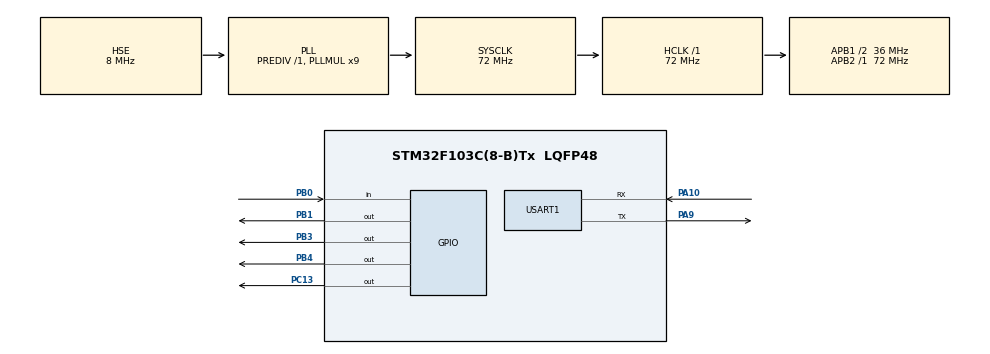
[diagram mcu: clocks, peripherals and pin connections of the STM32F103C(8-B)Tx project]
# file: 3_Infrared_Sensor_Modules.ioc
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Mcu.Family=STM32F1
RCC.PLLSourceVirtual=RCC_PLLSOURCE_HSE
PD1-OSC_OUT.Mode=HSE-External-Oscillator
PA10.Mode=Asynchronous
PC13-TAMPER-RTC.Signal=GPIO_Output
PD0-OSC_IN.Signal=RCC_OSC_IN
RCC.APB1CLKDivider=RCC_HCLK_DIV2
RCC.SYSCLKSource=RCC_SYSCLKSOURCE_PLLCLK
ProjectManager.StackSize=0x400
PD1-OSC_OUT.Signal=RCC_OSC_OUT
PA13.Signal=SYS_JTMS-SWDIO
PA9.Mode=Asynchronous
ProjectManager.TargetToolchain=STM32CubeIDE
RCC.HCLKFreq_Value=72000000
RCC.APB2TimFreq_Value=72000000
PA9.Signal=USART1_TX
RCC.USBFreq_Value=72000000
RCC.AHBFreq_Value=72000000
PD0-OSC_IN.Mode=HSE-External-Oscillator
board=custom
RCC.PLLMUL=RCC_PLL_MUL9
RCC.APB2Freq_Value=72000000
PA14.Mode=Serial_Wire
PA13.Mode=Serial_Wire
Mcu.Name=STM32F103C(8-B)Tx
VP_TIM1_VS_ClockSourceINT.Mode=Internal
PB3.Signal=GPIO_Output
RCC.SYSCLKFreq_VALUE=72000000
Mcu.Package=LQFP48
PB1.Signal=GPIO_Output
USART1.VirtualMode=VM_ASYNC
PA10.Signal=USART1_RX
PA14.Signal=SYS_JTCK-SWCLK
ProjectManager.HeapSize=0x200
NVIC.PriorityGroup=NVIC_PRIORITYGROUP_4
RCC.APB1TimFreq_Value=72000000
RCC.APB1Freq_Value=36000000
PB0.Signal=GPIO_Input
PB4.Signal=GPIO_Output

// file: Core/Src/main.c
/* USER CODE BEGIN Header */
/**
 ******************************************************************************
 * @file           : main.c
 * @brief          : Main program body
 ******************************************************************************
 * @attention
 *
 * <h2><center>&copy; Copyright (c) 2021 STMicroelectronics.
 * All rights reserved.</center></h2>
 *
 * This software component is licensed by ST under BSD 3-Clause license,
 * the "License"; You may not use this file except in compliance with the
 * License. You may obtain a copy of the License at:
 *                        opensource.org/licenses/BSD-3-Clause
 *
 ******************************************************************************
 */
/* infaredSensor.h
 * Released : 27/03/2021
 * Author   : danghoanelec@gmail.com
 * Short Descriptions:
  The library is using NEC Infrared Transmission Protocol to send/receive data
 * */

/* USER CODE END Header */
#include "main.h"

/* USER CODE BEGIN Includes */
//#include "stm32f1xx_hal_tim.h"
#include "infraredSensor.h"
/* USER CODE END Includes */

TIM_HandleTypeDef htim1;

UART_HandleTypeDef huart1;

void SystemClock_Config(void);
static void MX_GPIO_Init(void);
static void MX_TIM1_Init(void);
static void MX_USART1_UART_Init(void);

int main(void) {

	/* MCU Configuration--------------------------------------------------------*/

	/* Reset of all peripherals, Initializes the Flash interface and the Systick. */
	HAL_Init();

	/* Configure the system clock */
	SystemClock_Config();

	/* Initialize all configured peripherals */
	MX_GPIO_Init();
	MX_TIM1_Init();
	MX_USART1_UART_Init();
	/* USER CODE BEGIN 2 */
	Timer_1us_Init(72, htim1, TIM1);
	/* USER CODE END 2 */

	/* Infinite loop */
	/* USER CODE BEGIN WHILE */
	while (1) {
		uint32_t frm = NEC_Infrared_Read_specify(0x01);
		uint8_t data = NEC_Infrared_get_Data(frm);
		if(data != IR_RECEIVE_FAIL)
		{
			HAL_GPIO_TogglePin(GPIOC, GPIO_PIN_13);
		}
		//NEC_Infrared_Send_Data(0x01, 0x01);
	}
	/* USER CODE END 3 */
}

void SystemClock_Config(void) {
	RCC_OscInitTypeDef RCC_OscInitStruct = { 0 };
	RCC_ClkInitTypeDef RCC_ClkInitStruct = { 0 };

	/** Initializes the RCC Oscillators according to the specified parameters
	 * in the RCC_OscInitTypeDef structure.
	 */
	RCC_OscInitStruct.OscillatorType = RCC_OSCILLATORTYPE_HSE;
	RCC_OscInitStruct.HSEState = RCC_HSE_ON;
	RCC_OscInitStruct.HSEPredivValue = RCC_HSE_PREDIV_DIV1;
	RCC_OscInitStruct.HSIState = RCC_HSI_ON;
	RCC_OscInitStruct.PLL.PLLState = RCC_PLL_ON;
	RCC_OscInitStruct.PLL.PLLSource = RCC_PLLSOURCE_HSE;
	RCC_OscInitStruct.PLL.PLLMUL = RCC_PLL_MUL9;
	if (HAL_RCC_OscConfig(&RCC_OscInitStruct) != HAL_OK) {
		Error_Handler();
	}
	/** Initializes the CPU, AHB and APB buses clocks
	 */
	RCC_ClkInitStruct.ClockType = RCC_CLOCKTYPE_HCLK | RCC_CLOCKTYPE_SYSCLK
			| RCC_CLOCKTYPE_PCLK1 | RCC_CLOCKTYPE_PCLK2;
	RCC_ClkInitStruct.SYSCLKSource = RCC_SYSCLKSOURCE_PLLCLK;
	RCC_ClkInitStruct.AHBCLKDivider = RCC_SYSCLK_DIV1;
	RCC_ClkInitStruct.APB1CLKDivider = RCC_HCLK_DIV2;
	RCC_ClkInitStruct.APB2CLKDivider = RCC_HCLK_DIV1;

	if (HAL_RCC_ClockConfig(&RCC_ClkInitStruct, FLASH_LATENCY_2) != HAL_OK) {
		Error_Handler();
	}
}

static void MX_TIM1_Init(void) {

	TIM_ClockConfigTypeDef sClockSourceConfig = { 0 };
	TIM_MasterConfigTypeDef sMasterConfig = { 0 };

	htim1.Instance = TIM1;
	htim1.Init.Prescaler = 0;
	htim1.Init.CounterMode = TIM_COUNTERMODE_UP;
	htim1.Init.Period = 65535;
	htim1.Init.ClockDivision = TIM_CLOCKDIVISION_DIV1;
	htim1.Init.RepetitionCounter = 0;
	htim1.Init.AutoReloadPreload = TIM_AUTORELOAD_PRELOAD_DISABLE;
	if (HAL_TIM_Base_Init(&htim1) != HAL_OK) {
		Error_Handler();
	}
	sClockSourceConfig.ClockSource = TIM_CLOCKSOURCE_INTERNAL;
	if (HAL_TIM_ConfigClockSource(&htim1, &sClockSourceConfig) != HAL_OK) {
		Error_Handler();
	}
	sMasterConfig.MasterOutputTrigger = TIM_TRGO_RESET;
	sMasterConfig.MasterSlaveMode = TIM_MASTERSLAVEMODE_DISABLE;
	if (HAL_TIMEx_MasterConfigSynchronization(&htim1, &sMasterConfig)
			!= HAL_OK) {
		Error_Handler();
	}

}

static void MX_USART1_UART_Init(void) {

	huart1.Instance = USART1;
	huart1.Init.BaudRate = 115200;
	huart1.Init.WordLength = UART_WORDLENGTH_8B;
	huart1.Init.StopBits = UART_STOPBITS_1;
	huart1.Init.Parity = UART_PARITY_NONE;
	huart1.Init.Mode = UART_MODE_TX_RX;
	huart1.Init.HwFlowCtl = UART_HWCONTROL_NONE;
	huart1.Init.OverSampling = UART_OVERSAMPLING_16;
	if (HAL_UART_Init(&huart1) != HAL_OK) {
		Error_Handler();
	}

}

static void MX_GPIO_Init(void) {
	GPIO_InitTypeDef GPIO_InitStruct = { 0 };

	/* GPIO Ports Clock Enable */
	__HAL_RCC_GPIOC_CLK_ENABLE();
	__HAL_RCC_GPIOD_CLK_ENABLE();
	__HAL_RCC_GPIOB_CLK_ENABLE();
	__HAL_RCC_GPIOA_CLK_ENABLE();

	/*Configure GPIO pin Output Level */
	HAL_GPIO_WritePin(GPIOC, GPIO_PIN_13, GPIO_PIN_RESET);

	/*Configure GPIO pin Output Level */
	HAL_GPIO_WritePin(GPIOB, GPIO_PIN_1 | GPIO_PIN_3 | GPIO_PIN_4,
			GPIO_PIN_RESET);

	/*Configure GPIO pin : PC13 */
	GPIO_InitStruct.Pin = GPIO_PIN_13;
	GPIO_InitStruct.Mode = GPIO_MODE_OUTPUT_PP;
	GPIO_InitStruct.Pull = GPIO_NOPULL;
	GPIO_InitStruct.Speed = GPIO_SPEED_FREQ_LOW;
	HAL_GPIO_Init(GPIOC, &GPIO_InitStruct);

	/*Configure GPIO pin : PB0 */
	GPIO_InitStruct.Pin = GPIO_PIN_0;
	GPIO_InitStruct.Mode = GPIO_MODE_INPUT;
	GPIO_InitStruct.Pull = GPIO_NOPULL;
	HAL_GPIO_Init(GPIOB, &GPIO_InitStruct);

	/*Configure GPIO pins : PB1 PB3 PB4 */
	GPIO_InitStruct.Pin = GPIO_PIN_1 | GPIO_PIN_3 | GPIO_PIN_4;
	GPIO_InitStruct.Mode = GPIO_MODE_OUTPUT_PP;
	GPIO_InitStruct.Pull = GPIO_NOPULL;
	GPIO_InitStruct.Speed = GPIO_SPEED_FREQ_LOW;
	HAL_GPIO_Init(GPIOB, &GPIO_InitStruct);

}

void Error_Handler(void) {
	__disable_irq();
	while (1) {
	}
}

/************************ (C) COPYRIGHT STMicroelectronics *****END OF FILE****/
